# nrf9120_MLM1 register map
Vendor: Nordic Semiconductor; Series: nrf91; File version: 1
CPU: CM4 r0p1, little endian, MPU, FPU, 3 interrupt priority bits
Registers are 32-bit, read-write, reset 0x0 unless marked. A register's access mark holds for its fields unless they carry their own. Offsets are from the block's base; [hi:lo] are bit positions; lines under a group give offsets from that group; 'fields as' and 'values as' point back to an identical list.

## UARTE0 — UART with EasyDMA 0
Base 0x40008000
Same registers: UARTE1 0x40009000
0x00 TASKS_STARTRX wo — Start UART receiver
0x04 TASKS_STOPRX wo — Stop UART receiver
0x08 TASKS_STARTTX wo — Start UART transmitter
0x0C TASKS_STOPTX wo — Stop UART transmitter
0x1C TASKS_SUSPEND wo — Suspend UART transaction
0x20 TASKS_RESUME wo — Resume UART transaction
0x2C TASKS_FLUSHRX wo — Flush RX FIFO into RX buffer
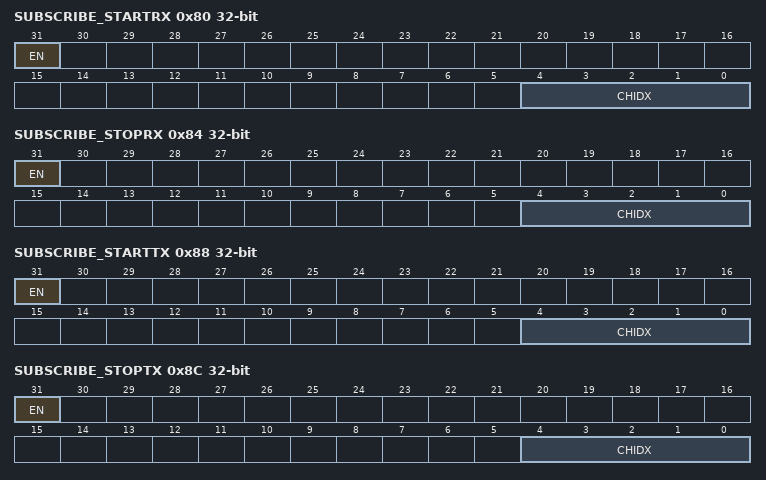
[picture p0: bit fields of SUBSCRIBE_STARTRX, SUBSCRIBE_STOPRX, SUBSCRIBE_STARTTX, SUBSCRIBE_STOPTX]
0x80 SUBSCRIBE_STARTRX — Subscribe configuration for TASKS_STARTRX
  [31] EN
    0=Disabled (Disable subscription); 1=Enabled (Enable subscription)
  [4:0] CHIDX — Channel the TASKS_STARTRX will subscribe to.
0x84 SUBSCRIBE_STOPRX — Subscribe configuration for TASKS_STOPRX
  [31] EN
    values as SUBSCRIBE_STARTRX.EN
  [4:0] CHIDX — Channel the TASKS_STOPRX will subscribe to.
0x88 SUBSCRIBE_STARTTX — Subscribe configuration for TASKS_STARTTX
  [31] EN
    values as SUBSCRIBE_STARTRX.EN
  [4:0] CHIDX — Channel the TASKS_STARTTX will subscribe to.
0x8C SUBSCRIBE_STOPTX — Subscribe configuration for TASKS_STOPTX
  [31] EN
    values as SUBSCRIBE_STARTRX.EN
  [4:0] CHIDX — Channel the TASKS_STOPTX will subscribe to.
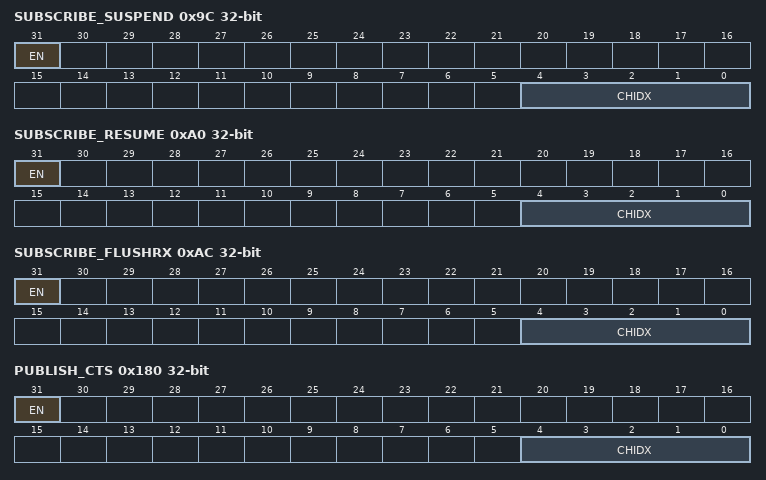
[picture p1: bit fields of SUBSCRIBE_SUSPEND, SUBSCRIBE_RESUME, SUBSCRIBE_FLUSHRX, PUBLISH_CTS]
0x9C SUBSCRIBE_SUSPEND — Subscribe configuration for TASKS_SUSPEND
  [31] EN
    values as SUBSCRIBE_STARTRX.EN
  [4:0] CHIDX — Channel the TASKS_SUSPEND will subscribe to.
0xA0 SUBSCRIBE_RESUME — Subscribe configuration for TASKS_RESUME
  [31] EN
    values as SUBSCRIBE_STARTRX.EN
  [4:0] CHIDX — Channel the TASKS_RESUME will subscribe to.
0xAC SUBSCRIBE_FLUSHRX — Subscribe configuration for TASKS_FLUSHRX
  [31] EN
    values as SUBSCRIBE_STARTRX.EN
  [4:0] CHIDX — Channel the TASKS_FLUSHRX will subscribe to.
0x100 EVENTS_CTS — CTS is activated (set low). Clear To Send.
0x104 EVENTS_NCTS — CTS is deactivated (set high). Not Clear To Send.
0x108 EVENTS_RXDRDY — Data received in RXD (but potentially not yet transferred to Data RAM)
0x110 EVENTS_ENDRX — Receive buffer is filled up
0x11C EVENTS_TXDRDY — Data sent from TXD
0x120 EVENTS_ENDTX — Last TX byte transmitted
0x124 EVENTS_ERROR — Error detected
0x144 EVENTS_RXTO — Receiver timeout
0x14C EVENTS_RXSTARTED — UART receiver has started
0x150 EVENTS_TXSTARTED — UART transmitter has started
0x154 EVENTS_RTS — RX FIFO has only room for four more bytes before it overflows
0x158 EVENTS_TXSTOPPED — Transmitter stopped
0x180 PUBLISH_CTS — Publish configuration for EVENTS_CTS
  [31] EN
    0=Disabled (Disable publishing); 1=Enabled (Enable publishing)
  [4:0] CHIDX — Channel the EVENTS_CTS will subscribe to.
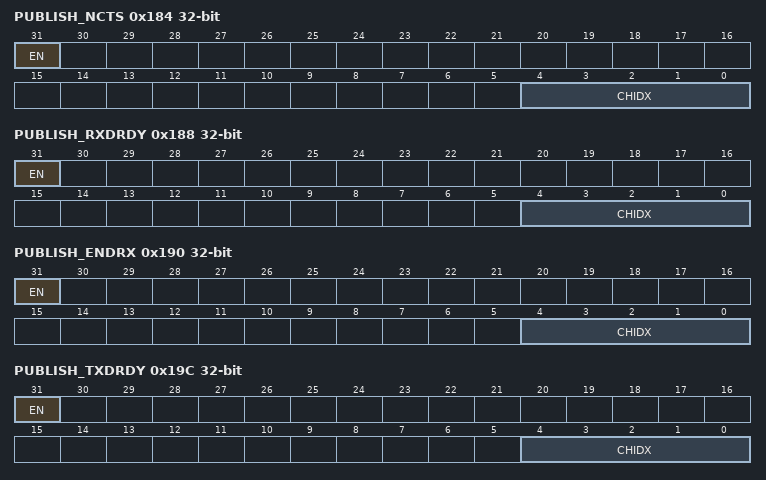
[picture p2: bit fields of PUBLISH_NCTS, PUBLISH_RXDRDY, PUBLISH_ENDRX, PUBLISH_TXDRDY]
0x184 PUBLISH_NCTS — Publish configuration for EVENTS_NCTS
  [31] EN
    values as PUBLISH_CTS.EN
  [4:0] CHIDX — Channel the EVENTS_NCTS will subscribe to.
0x188 PUBLISH_RXDRDY — Publish configuration for EVENTS_RXDRDY
  [31] EN
    values as PUBLISH_CTS.EN
  [4:0] CHIDX — Channel the EVENTS_RXDRDY will subscribe to.
0x190 PUBLISH_ENDRX — Publish configuration for EVENTS_ENDRX
  [31] EN
    values as PUBLISH_CTS.EN
  [4:0] CHIDX — Channel the EVENTS_ENDRX will subscribe to.
0x19C PUBLISH_TXDRDY — Publish configuration for EVENTS_TXDRDY
  [31] EN
    values as PUBLISH_CTS.EN
  [4:0] CHIDX — Channel the EVENTS_TXDRDY will subscribe to.
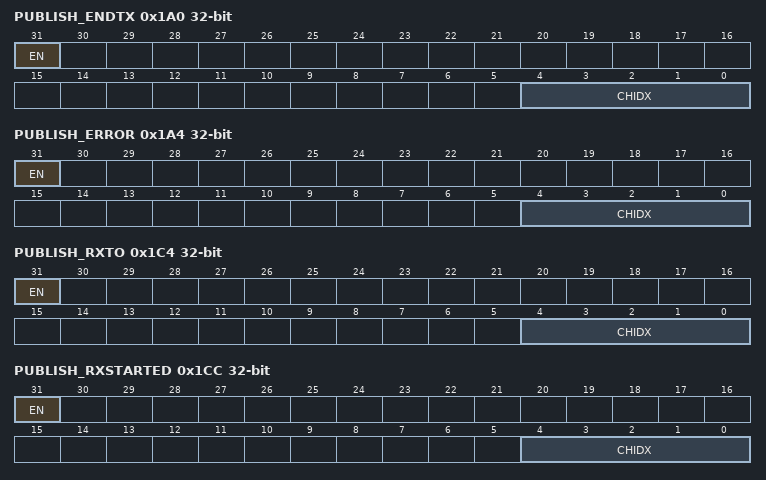
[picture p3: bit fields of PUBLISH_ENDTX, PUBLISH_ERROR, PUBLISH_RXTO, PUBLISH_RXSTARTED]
0x1A0 PUBLISH_ENDTX — Publish configuration for EVENTS_ENDTX
  [31] EN
    values as PUBLISH_CTS.EN
  [4:0] CHIDX — Channel the EVENTS_ENDTX will subscribe to.
0x1A4 PUBLISH_ERROR — Publish configuration for EVENTS_ERROR
  [31] EN
    values as PUBLISH_CTS.EN
  [4:0] CHIDX — Channel the EVENTS_ERROR will subscribe to.
0x1C4 PUBLISH_RXTO — Publish configuration for EVENTS_RXTO
  [31] EN
    values as PUBLISH_CTS.EN
  [4:0] CHIDX — Channel the EVENTS_RXTO will subscribe to.
0x1CC PUBLISH_RXSTARTED — Publish configuration for EVENTS_RXSTARTED
  [31] EN
    values as PUBLISH_CTS.EN
  [4:0] CHIDX — Channel the EVENTS_RXSTARTED will subscribe to.
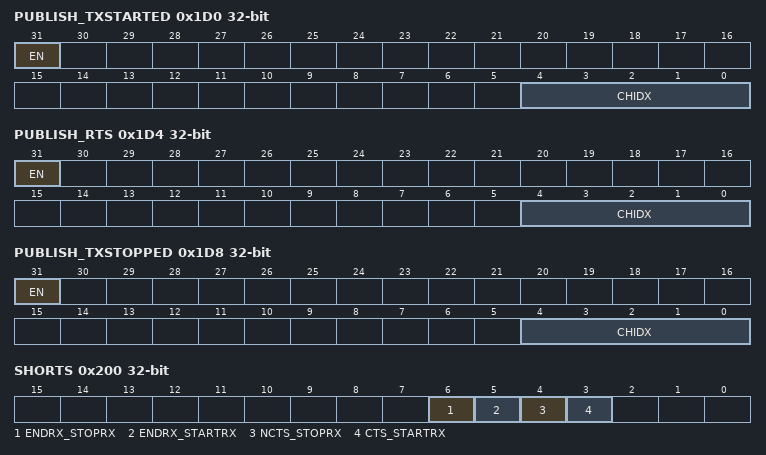
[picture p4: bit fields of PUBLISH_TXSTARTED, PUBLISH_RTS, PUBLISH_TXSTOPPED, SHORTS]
0x1D0 PUBLISH_TXSTARTED — Publish configuration for EVENTS_TXSTARTED
  [31] EN
    values as PUBLISH_CTS.EN
  [4:0] CHIDX — Channel the EVENTS_TXSTARTED will subscribe to.
0x1D4 PUBLISH_RTS — Publish configuration for EVENTS_RTS
  [31] EN
    values as PUBLISH_CTS.EN
  [4:0] CHIDX — Channel the EVENTS_RTS will subscribe to.
0x1D8 PUBLISH_TXSTOPPED — Publish configuration for EVENTS_TXSTOPPED
  [31] EN
    values as PUBLISH_CTS.EN
  [4:0] CHIDX — Channel the EVENTS_TXSTOPPED will subscribe to.
0x200 SHORTS — Shortcut register
  [all] fields
    0=Disabled (Disable shortcut); 1=Enabled (Enable shortcut)
  [6] ENDRX_STOPRX — Shortcut between ENDRX event and STOPRX task
  [5] ENDRX_STARTRX — Shortcut between ENDRX event and STARTRX task
  [4] NCTS_STOPRX — Shortcut between NCTS event and STOPRX task
  [3] CTS_STARTRX — Shortcut between CTS event and STARTRX task
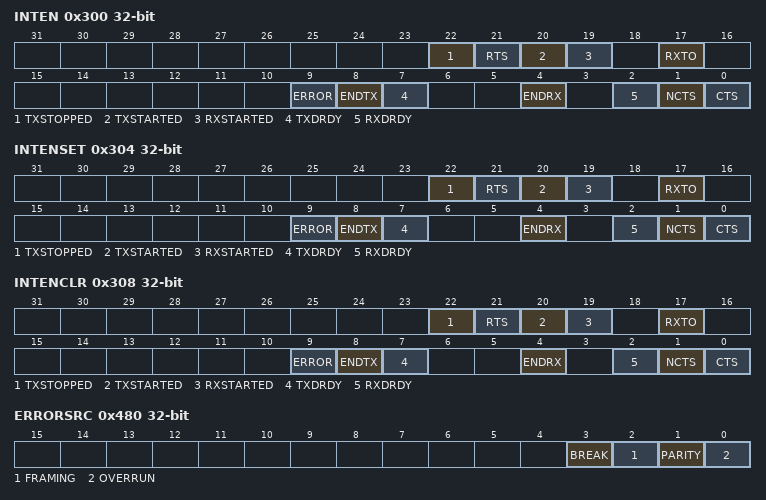
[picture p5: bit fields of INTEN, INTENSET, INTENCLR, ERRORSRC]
0x300 INTEN — Enable or disable interrupt
  [all] fields
    0=Disabled; 1=Enabled
  [22] TXSTOPPED — Enable or disable interrupt for TXSTOPPED event
  [21] RTS — Enable or disable interrupt for RTS event
  [20] TXSTARTED — Enable or disable interrupt for TXSTARTED event
  [19] RXSTARTED — Enable or disable interrupt for RXSTARTED event
  [17] RXTO — Enable or disable interrupt for RXTO event
  [9] ERROR — Enable or disable interrupt for ERROR event
  [8] ENDTX — Enable or disable interrupt for ENDTX event
  [7] TXDRDY — Enable or disable interrupt for TXDRDY event
  [4] ENDRX — Enable or disable interrupt for ENDRX event
  [2] RXDRDY — Enable or disable interrupt for RXDRDY event
  [1] NCTS — Enable or disable interrupt for NCTS event
  [0] CTS — Enable or disable interrupt for CTS event
0x304 INTENSET — Enable interrupt
  [all] fields
    on read: 0=Disabled (Read: Disabled); 1=Enabled (Read: Enabled) | on write: 1=Set (Enable)
  [22] TXSTOPPED — Write '1' to Enable interrupt for TXSTOPPED event
  [21] RTS — Write '1' to Enable interrupt for RTS event
  [20] TXSTARTED — Write '1' to Enable interrupt for TXSTARTED event
  [19] RXSTARTED — Write '1' to Enable interrupt for RXSTARTED event
  [17] RXTO — Write '1' to Enable interrupt for RXTO event
  [9] ERROR — Write '1' to Enable interrupt for ERROR event
  [8] ENDTX — Write '1' to Enable interrupt for ENDTX event
  [7] TXDRDY — Write '1' to Enable interrupt for TXDRDY event
  [4] ENDRX — Write '1' to Enable interrupt for ENDRX event
  [2] RXDRDY — Write '1' to Enable interrupt for RXDRDY event
  [1] NCTS — Write '1' to Enable interrupt for NCTS event
  [0] CTS — Write '1' to Enable interrupt for CTS event
0x308 INTENCLR — Disable interrupt
  [all] fields
    on read: 0=Disabled (Read: Disabled); 1=Enabled (Read: Enabled) | on write: 1=Clear (Disable)
  [22] TXSTOPPED — Write '1' to Disable interrupt for TXSTOPPED event
  [21] RTS — Write '1' to Disable interrupt for RTS event
  [20] TXSTARTED — Write '1' to Disable interrupt for TXSTARTED event
  [19] RXSTARTED — Write '1' to Disable interrupt for RXSTARTED event
  [17] RXTO — Write '1' to Disable interrupt for RXTO event
  [9] ERROR — Write '1' to Disable interrupt for ERROR event
  [8] ENDTX — Write '1' to Disable interrupt for ENDTX event
  [7] TXDRDY — Write '1' to Disable interrupt for TXDRDY event
  [4] ENDRX — Write '1' to Disable interrupt for ENDRX event
  [2] RXDRDY — Write '1' to Disable interrupt for RXDRDY event
  [1] NCTS — Write '1' to Disable interrupt for NCTS event
  [0] CTS — Write '1' to Disable interrupt for CTS event
0x480 ERRORSRC write-1-clears — Error source Note : this register is read / write one to clear.
  [all] fields
    on read: 0=NotPresent (Read: error not present); 1=Present (Read: error present)
  [3] BREAK — Break condition
  [2] FRAMING — Framing error occurred
  [1] PARITY — Parity error
  [0] OVERRUN — Overrun error
0x500 ENABLE — Enable UART
  [3:0] ENABLE — Enable or disable UARTE
    0=Disabled (Disable UARTE); 8=Enabled (Enable UARTE)
0x508 PSEL group — Unspecified
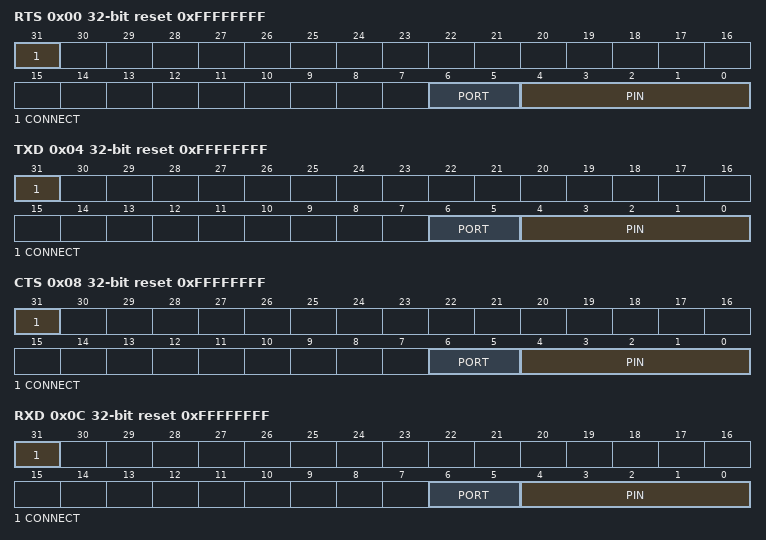
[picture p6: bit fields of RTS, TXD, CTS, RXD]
  0x00 RTS reset 0xFFFFFFFF — Pin select for RTS signal
    [31] CONNECT — Connection
      1=Disconnected; 0=Connected
    [6:5] PORT — Port number
    [4:0] PIN — Pin number
  0x04 TXD reset 0xFFFFFFFF — Pin select for TXD signal
    fields as PSEL.RTS
  0x08 CTS reset 0xFFFFFFFF — Pin select for CTS signal
    fields as PSEL.RTS
  0x0C RXD reset 0xFFFFFFFF — Pin select for RXD signal
    fields as PSEL.RTS
0x524 BAUDRATE reset 0x4000000 — Baud rate. Accuracy depends on the HFCLK source selected.
  [31:0] BAUDRATE
    0x4F000=Baud1200 (1200 baud (actual rate: 1205)); 0x9D000=Baud2400 (2400 baud (actual rate: 2396)); 0x13B000=Baud4800 (4800 baud (actual rate: 4808)); 0x275000=Baud9600 (9600 baud (actual rate: 9598)); 0x3AF000=Baud14400 (14400 baud (actual rate: 14401)); 0x4EA000=Baud19200 (19200 baud (actual rate: 19208)); 0x75C000=Baud28800 (28800 baud (actual rate: 28777)); 0x9D0000=Baud38400 (38400 baud (actual rate: 38369)); 0xEB0000=Baud57600 (57600 baud (actual rate: 57554)); 0x13A9000=Baud76800 (76800 baud (actual rate: 76923)); 0x1D60000=Baud115200 (115200 baud (actual rate: 115108)); 0x3B00000=Baud230400 (230400 baud (actual rate: 231884)); 0x4000000=Baud250000 (250000 baud); 0x7400000=Baud460800 (460800 baud (actual rate: 457143)); 0xF000000=Baud921600 (921600 baud (actual rate: 941176)); 0x10000000=Baud1M (1Mega baud)
0x534 RXD group — RXD EasyDMA channel
  0x00 PTR — Data pointer
  0x04 MAXCNT — Maximum number of bytes in receive buffer
    [7:0] MAXCNT
  0x08 AMOUNT ro — Number of bytes transferred in the last transaction
    [7:0] AMOUNT
0x544 TXD group — TXD EasyDMA channel
  0x00 PTR — Data pointer
  0x04 MAXCNT — Maximum number of bytes in transmit buffer
    [7:0] MAXCNT
  0x08 AMOUNT ro — Number of bytes transferred in the last transaction
    [7:0] AMOUNT
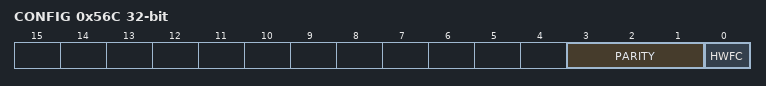
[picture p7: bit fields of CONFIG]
0x56C CONFIG — Configuration of parity and hardware flow control
  [3:1] PARITY
    0=Excluded (Exclude parity bit); 7=Included (Include parity bit)
  [0] HWFC — Hardware flow control
    0=Disabled; 1=Enabled
0xFFC POWER reset 0x1 — Peripheral power control
  [0] POWER — Peripheral power control. The peripheral and its registers will be reset to its initial state by switching the peripheral off and then back on again.
    0=Disabled (Peripheral is powered off); 1=Enabled (Peripheral is powered on)
